VERSION "1.0.0"

NS_ :

BS_:

BU_: KRABBY_HOST LEG_NODE

BO_ 256 SET_DUTY: 36 KRABBY_HOST
 SG_ L1_J1 : 0|16@1- (0.001,0) [-1|1] "" KRABBY_HOST
 SG_ L1_J2 : 16|16@1- (0.001,0) [-1|1] "" KRABBY_HOST
 SG_ L1_J3 : 32|16@1- (0.001,0) [-1|1] "" KRABBY_HOST
 SG_ L2_J1 : 48|16@1- (0.001,0) [-1|1] "" KRABBY_HOST
 SG_ L2_J2 : 64|16@1- (0.001,0) [-1|1] "" KRABBY_HOST
 SG_ L2_J3 : 80|16@1- (0.001,0) [-1|1] "" KRABBY_HOST
 SG_ L3_J1 : 96|16@1- (0.001,0) [-1|1] "" KRABBY_HOST
 SG_ L3_J2 : 112|16@1- (0.001,0) [-1|1] "" KRABBY_HOST
 SG_ L3_J3 : 128|16@1- (0.001,0) [-1|1] "" KRABBY_HOST
 SG_ L4_J1 : 144|16@1- (0.001,0) [-1|1] "" KRABBY_HOST
 SG_ L4_J2 : 160|16@1- (0.001,0) [-1|1] "" KRABBY_HOST
 SG_ L4_J3 : 176|16@1- (0.001,0) [-1|1] "" KRABBY_HOST
 SG_ L5_J1 : 192|16@1- (0.001,0) [-1|1] "" KRABBY_HOST
 SG_ L5_J2 : 208|16@1- (0.001,0) [-1|1] "" KRABBY_HOST
 SG_ L5_J3 : 224|16@1- (0.001,0) [-1|1] "" KRABBY_HOST
 SG_ L6_J1 : 240|16@1- (0.001,0) [-1|1] "" KRABBY_HOST
 SG_ L6_J2 : 256|16@1- (0.001,0) [-1|1] "" KRABBY_HOST
 SG_ L6_J3 : 272|16@1- (0.001,0) [-1|1] "" KRABBY_HOST

BO_ 385 CALIBRATE_1: 1 KRABBY_HOST
 SG_ joint : 0|8@1+ (1,0) [2|3] "" KRABBY_HOST

BO_ 386 CALIBRATE_2: 1 KRABBY_HOST
 SG_ joint : 0|8@1+ (1,0) [2|3] "" KRABBY_HOST

BO_ 387 CALIBRATE_3: 1 KRABBY_HOST
 SG_ joint : 0|8@1+ (1,0) [2|3] "" KRABBY_HOST

BO_ 388 CALIBRATE_4: 1 KRABBY_HOST
 SG_ joint : 0|8@1+ (1,0) [2|3] "" KRABBY_HOST

BO_ 389 CALIBRATE_5: 1 KRABBY_HOST
 SG_ joint : 0|8@1+ (1,0) [2|3] "" KRABBY_HOST

BO_ 390 CALIBRATE_6: 1 KRABBY_HOST
 SG_ joint : 0|8@1+ (1,0) [2|3] "" KRABBY_HOST

BO_ 513 TELEMETRY_1: 48 LEG_NODE
 SG_ J1_HALL : 0|32@1- (1,0) [-2147483648|2147483647] "" KRABBY_HOST
 SG_ J1_DUTY : 32|16@1- (0.001,0) [-1|1] "" KRABBY_HOST
 SG_ J1_POT : 48|12@1+ (1,0) [0|4095] "" KRABBY_HOST
 SG_ J1_FAULT : 60|1@1+ (1,0) [0|1] "" KRABBY_HOST
 SG_ J1_CALIBRATING : 61|1@1+ (1,0) [0|1] "" KRABBY_HOST
 SG_ J1_CALIBRATED : 62|1@1+ (1,0) [0|1] "" KRABBY_HOST
 SG_ J1_POSITION : 64|64@1+ (1,0) [-1.7976931348623157E+308|1.7976931348623157E+308] "" KRABBY_HOST
 SG_ J2_HALL : 128|32@1- (1,0) [-2147483648|2147483647] "" KRABBY_HOST
 SG_ J2_DUTY : 160|16@1- (0.001,0) [-1|1] "" KRABBY_HOST
 SG_ J2_POT : 176|12@1+ (1,0) [0|4095] "" KRABBY_HOST
 SG_ J2_FAULT : 188|1@1+ (1,0) [0|1] "" KRABBY_HOST
 SG_ J2_CALIBRATING : 189|1@1+ (1,0) [0|1] "" KRABBY_HOST
 SG_ J2_CALIBRATED : 190|1@1+ (1,0) [0|1] "" KRABBY_HOST
 SG_ J2_POSITION : 192|64@1+ (1,0) [-1.7976931348623157E+308|1.7976931348623157E+308] "" KRABBY_HOST
 SG_ J3_HALL : 256|32@1- (1,0) [-2147483648|2147483647] "" KRABBY_HOST
 SG_ J3_DUTY : 288|16@1- (0.001,0) [-1|1] "" KRABBY_HOST
 SG_ J3_POT : 304|12@1+ (1,0) [0|4095] "" KRABBY_HOST
 SG_ J3_FAULT : 316|1@1+ (1,0) [0|1] "" KRABBY_HOST
 SG_ J3_CALIBRATING : 317|1@1+ (1,0) [0|1] "" KRABBY_HOST
 SG_ J3_CALIBRATED : 318|1@1+ (1,0) [0|1] "" KRABBY_HOST
 SG_ J3_POSITION : 320|64@1+ (1,0) [-1.7976931348623157E+308|1.7976931348623157E+308] "" KRABBY_HOST

BO_ 514 TELEMETRY_2: 48 LEG_NODE
 SG_ J1_HALL : 0|32@1- (1,0) [-2147483648|2147483647] "" KRABBY_HOST
 SG_ J1_DUTY : 32|16@1- (0.001,0) [-1|1] "" KRABBY_HOST
 SG_ J1_POT : 48|12@1+ (1,0) [0|4095] "" KRABBY_HOST
 SG_ J1_FAULT : 60|1@1+ (1,0) [0|1] "" KRABBY_HOST
 SG_ J1_CALIBRATING : 61|1@1+ (1,0) [0|1] "" KRABBY_HOST
 SG_ J1_CALIBRATED : 62|1@1+ (1,0) [0|1] "" KRABBY_HOST
 SG_ J1_POSITION : 64|64@1+ (1,0) [-1.7976931348623157E+308|1.7976931348623157E+308] "" KRABBY_HOST
 SG_ J2_HALL : 128|32@1- (1,0) [-2147483648|2147483647] "" KRABBY_HOST
 SG_ J2_DUTY : 160|16@1- (0.001,0) [-1|1] "" KRABBY_HOST
 SG_ J2_POT : 176|12@1+ (1,0) [0|4095] "" KRABBY_HOST
 SG_ J2_FAULT : 188|1@1+ (1,0) [0|1] "" KRABBY_HOST
 SG_ J2_CALIBRATING : 189|1@1+ (1,0) [0|1] "" KRABBY_HOST
 SG_ J2_CALIBRATED : 190|1@1+ (1,0) [0|1] "" KRABBY_HOST
 SG_ J2_POSITION : 192|64@1+ (1,0) [-1.7976931348623157E+308|1.7976931348623157E+308] "" KRABBY_HOST
 SG_ J3_HALL : 256|32@1- (1,0) [-2147483648|2147483647] "" KRABBY_HOST
 SG_ J3_DUTY : 288|16@1- (0.001,0) [-1|1] "" KRABBY_HOST
 SG_ J3_POT : 304|12@1+ (1,0) [0|4095] "" KRABBY_HOST
 SG_ J3_FAULT : 316|1@1+ (1,0) [0|1] "" KRABBY_HOST
 SG_ J3_CALIBRATING : 317|1@1+ (1,0) [0|1] "" KRABBY_HOST
 SG_ J3_CALIBRATED : 318|1@1+ (1,0) [0|1] "" KRABBY_HOST
 SG_ J3_POSITION : 320|64@1+ (1,0) [-1.7976931348623157E+308|1.7976931348623157E+308] "" KRABBY_HOST

BO_ 515 TELEMETRY_3: 48 LEG_NODE
 SG_ J1_HALL : 0|32@1- (1,0) [-2147483648|2147483647] "" KRABBY_HOST
 SG_ J1_DUTY : 32|16@1- (0.001,0) [-1|1] "" KRABBY_HOST
 SG_ J1_POT : 48|12@1+ (1,0) [0|4095] "" KRABBY_HOST
 SG_ J1_FAULT : 60|1@1+ (1,0) [0|1] "" KRABBY_HOST
 SG_ J1_CALIBRATING : 61|1@1+ (1,0) [0|1] "" KRABBY_HOST
 SG_ J1_CALIBRATED : 62|1@1+ (1,0) [0|1] "" KRABBY_HOST
 SG_ J1_POSITION : 64|64@1+ (1,0) [-1.7976931348623157E+308|1.7976931348623157E+308] "" KRABBY_HOST
 SG_ J2_HALL : 128|32@1- (1,0) [-2147483648|2147483647] "" KRABBY_HOST
 SG_ J2_DUTY : 160|16@1- (0.001,0) [-1|1] "" KRABBY_HOST
 SG_ J2_POT : 176|12@1+ (1,0) [0|4095] "" KRABBY_HOST
 SG_ J2_FAULT : 188|1@1+ (1,0) [0|1] "" KRABBY_HOST
 SG_ J2_CALIBRATING : 189|1@1+ (1,0) [0|1] "" KRABBY_HOST
 SG_ J2_CALIBRATED : 190|1@1+ (1,0) [0|1] "" KRABBY_HOST
 SG_ J2_POSITION : 192|64@1+ (1,0) [-1.7976931348623157E+308|1.7976931348623157E+308] "" KRABBY_HOST
 SG_ J3_HALL : 256|32@1- (1,0) [-2147483648|2147483647] "" KRABBY_HOST
 SG_ J3_DUTY : 288|16@1- (0.001,0) [-1|1] "" KRABBY_HOST
 SG_ J3_POT : 304|12@1+ (1,0) [0|4095] "" KRABBY_HOST
 SG_ J3_FAULT : 316|1@1+ (1,0) [0|1] "" KRABBY_HOST
 SG_ J3_CALIBRATING : 317|1@1+ (1,0) [0|1] "" KRABBY_HOST
 SG_ J3_CALIBRATED : 318|1@1+ (1,0) [0|1] "" KRABBY_HOST
 SG_ J3_POSITION : 320|64@1+ (1,0) [-1.7976931348623157E+308|1.7976931348623157E+308] "" KRABBY_HOST

BO_ 516 TELEMETRY_4: 48 LEG_NODE
 SG_ J1_HALL : 0|32@1- (1,0) [-2147483648|2147483647] "" KRABBY_HOST
 SG_ J1_DUTY : 32|16@1- (0.001,0) [-1|1] "" KRABBY_HOST
 SG_ J1_POT : 48|12@1+ (1,0) [0|4095] "" KRABBY_HOST
 SG_ J1_FAULT : 60|1@1+ (1,0) [0|1] "" KRABBY_HOST
 SG_ J1_CALIBRATING : 61|1@1+ (1,0) [0|1] "" KRABBY_HOST
 SG_ J1_CALIBRATED : 62|1@1+ (1,0) [0|1] "" KRABBY_HOST
 SG_ J1_POSITION : 64|64@1+ (1,0) [-1.7976931348623157E+308|1.7976931348623157E+308] "" KRABBY_HOST
 SG_ J2_HALL : 128|32@1- (1,0) [-2147483648|2147483647] "" KRABBY_HOST
 SG_ J2_DUTY : 160|16@1- (0.001,0) [-1|1] "" KRABBY_HOST
 SG_ J2_POT : 176|12@1+ (1,0) [0|4095] "" KRABBY_HOST
 SG_ J2_FAULT : 188|1@1+ (1,0) [0|1] "" KRABBY_HOST
 SG_ J2_CALIBRATING : 189|1@1+ (1,0) [0|1] "" KRABBY_HOST
 SG_ J2_CALIBRATED : 190|1@1+ (1,0) [0|1] "" KRABBY_HOST
 SG_ J2_POSITION : 192|64@1+ (1,0) [-1.7976931348623157E+308|1.7976931348623157E+308] "" KRABBY_HOST
 SG_ J3_HALL : 256|32@1- (1,0) [-2147483648|2147483647] "" KRABBY_HOST
 SG_ J3_DUTY : 288|16@1- (0.001,0) [-1|1] "" KRABBY_HOST
 SG_ J3_POT : 304|12@1+ (1,0) [0|4095] "" KRABBY_HOST
 SG_ J3_FAULT : 316|1@1+ (1,0) [0|1] "" KRABBY_HOST
 SG_ J3_CALIBRATING : 317|1@1+ (1,0) [0|1] "" KRABBY_HOST
 SG_ J3_CALIBRATED : 318|1@1+ (1,0) [0|1] "" KRABBY_HOST
 SG_ J3_POSITION : 320|64@1+ (1,0) [-1.7976931348623157E+308|1.7976931348623157E+308] "" KRABBY_HOST

BO_ 517 TELEMETRY_5: 48 LEG_NODE
 SG_ J1_HALL : 0|32@1- (1,0) [-2147483648|2147483647] "" KRABBY_HOST
 SG_ J1_DUTY : 32|16@1- (0.001,0) [-1|1] "" KRABBY_HOST
 SG_ J1_POT : 48|12@1+ (1,0) [0|4095] "" KRABBY_HOST
 SG_ J1_FAULT : 60|1@1+ (1,0) [0|1] "" KRABBY_HOST
 SG_ J1_CALIBRATING : 61|1@1+ (1,0) [0|1] "" KRABBY_HOST
 SG_ J1_CALIBRATED : 62|1@1+ (1,0) [0|1] "" KRABBY_HOST
 SG_ J1_POSITION : 64|64@1+ (1,0) [-1.7976931348623157E+308|1.7976931348623157E+308] "" KRABBY_HOST
 SG_ J2_HALL : 128|32@1- (1,0) [-2147483648|2147483647] "" KRABBY_HOST
 SG_ J2_DUTY : 160|16@1- (0.001,0) [-1|1] "" KRABBY_HOST
 SG_ J2_POT : 176|12@1+ (1,0) [0|4095] "" KRABBY_HOST
 SG_ J2_FAULT : 188|1@1+ (1,0) [0|1] "" KRABBY_HOST
 SG_ J2_CALIBRATING : 189|1@1+ (1,0) [0|1] "" KRABBY_HOST
 SG_ J2_CALIBRATED : 190|1@1+ (1,0) [0|1] "" KRABBY_HOST
 SG_ J2_POSITION : 192|64@1+ (1,0) [-1.7976931348623157E+308|1.7976931348623157E+308] "" KRABBY_HOST
 SG_ J3_HALL : 256|32@1- (1,0) [-2147483648|2147483647] "" KRABBY_HOST
 SG_ J3_DUTY : 288|16@1- (0.001,0) [-1|1] "" KRABBY_HOST
 SG_ J3_POT : 304|12@1+ (1,0) [0|4095] "" KRABBY_HOST
 SG_ J3_FAULT : 316|1@1+ (1,0) [0|1] "" KRABBY_HOST
 SG_ J3_CALIBRATING : 317|1@1+ (1,0) [0|1] "" KRABBY_HOST
 SG_ J3_CALIBRATED : 318|1@1+ (1,0) [0|1] "" KRABBY_HOST
 SG_ J3_POSITION : 320|64@1+ (1,0) [-1.7976931348623157E+308|1.7976931348623157E+308] "" KRABBY_HOST

BO_ 518 TELEMETRY_6: 48 LEG_NODE
 SG_ J1_HALL : 0|32@1- (1,0) [-2147483648|2147483647] "" KRABBY_HOST
 SG_ J1_DUTY : 32|16@1- (0.001,0) [-1|1] "" KRABBY_HOST
 SG_ J1_POT : 48|12@1+ (1,0) [0|4095] "" KRABBY_HOST
 SG_ J1_FAULT : 60|1@1+ (1,0) [0|1] "" KRABBY_HOST
 SG_ J1_CALIBRATING : 61|1@1+ (1,0) [0|1] "" KRABBY_HOST
 SG_ J1_CALIBRATED : 62|1@1+ (1,0) [0|1] "" KRABBY_HOST
 SG_ J1_POSITION : 64|64@1+ (1,0) [-1.7976931348623157E+308|1.7976931348623157E+308] "" KRABBY_HOST
 SG_ J2_HALL : 128|32@1- (1,0) [-2147483648|2147483647] "" KRABBY_HOST
 SG_ J2_DUTY : 160|16@1- (0.001,0) [-1|1] "" KRABBY_HOST
 SG_ J2_POT : 176|12@1+ (1,0) [0|4095] "" KRABBY_HOST
 SG_ J2_FAULT : 188|1@1+ (1,0) [0|1] "" KRABBY_HOST
 SG_ J2_CALIBRATING : 189|1@1+ (1,0) [0|1] "" KRABBY_HOST
 SG_ J2_CALIBRATED : 190|1@1+ (1,0) [0|1] "" KRABBY_HOST
 SG_ J2_POSITION : 192|64@1+ (1,0) [-1.7976931348623157E+308|1.7976931348623157E+308] "" KRABBY_HOST
 SG_ J3_HALL : 256|32@1- (1,0) [-2147483648|2147483647] "" KRABBY_HOST
 SG_ J3_DUTY : 288|16@1- (0.001,0) [-1|1] "" KRABBY_HOST
 SG_ J3_POT : 304|12@1+ (1,0) [0|4095] "" KRABBY_HOST
 SG_ J3_FAULT : 316|1@1+ (1,0) [0|1] "" KRABBY_HOST
 SG_ J3_CALIBRATING : 317|1@1+ (1,0) [0|1] "" KRABBY_HOST
 SG_ J3_CALIBRATED : 318|1@1+ (1,0) [0|1] "" KRABBY_HOST
 SG_ J3_POSITION : 320|64@1+ (1,0) [-1.7976931348623157E+308|1.7976931348623157E+308] "" KRABBY_HOST

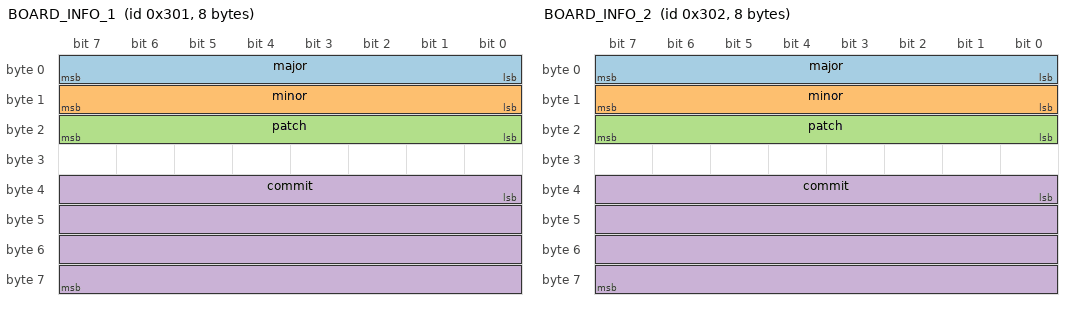
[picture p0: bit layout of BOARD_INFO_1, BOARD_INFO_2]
BO_ 769 BOARD_INFO_1: 8 LEG_NODE
 SG_ major : 0|8@1+ (1,0) [0|255] "" KRABBY_HOST
 SG_ minor : 8|8@1+ (1,0) [0|255] "" KRABBY_HOST
 SG_ patch : 16|8@1+ (1,0) [0|255] "" KRABBY_HOST
 SG_ commit : 32|32@1+ (1,0) [0|4294967295] "" KRABBY_HOST

BO_ 770 BOARD_INFO_2: 8 LEG_NODE
 SG_ major : 0|8@1+ (1,0) [0|255] "" KRABBY_HOST
 SG_ minor : 8|8@1+ (1,0) [0|255] "" KRABBY_HOST
 SG_ patch : 16|8@1+ (1,0) [0|255] "" KRABBY_HOST
 SG_ commit : 32|32@1+ (1,0) [0|4294967295] "" KRABBY_HOST

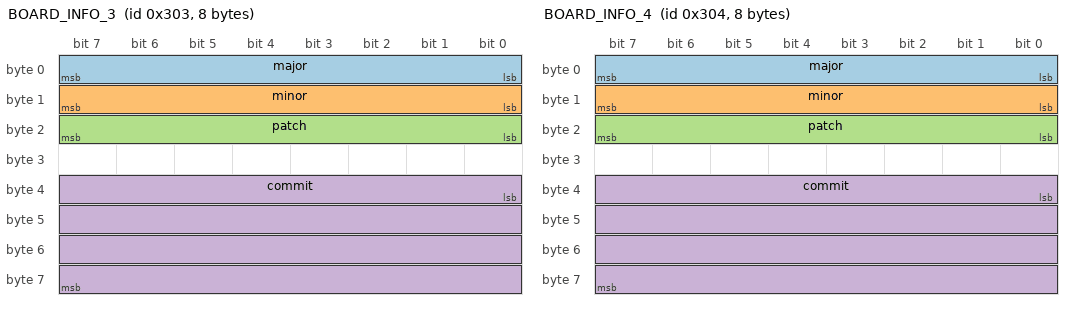
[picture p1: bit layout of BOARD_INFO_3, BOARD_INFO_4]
BO_ 771 BOARD_INFO_3: 8 LEG_NODE
 SG_ major : 0|8@1+ (1,0) [0|255] "" KRABBY_HOST
 SG_ minor : 8|8@1+ (1,0) [0|255] "" KRABBY_HOST
 SG_ patch : 16|8@1+ (1,0) [0|255] "" KRABBY_HOST
 SG_ commit : 32|32@1+ (1,0) [0|4294967295] "" KRABBY_HOST

BO_ 772 BOARD_INFO_4: 8 LEG_NODE
 SG_ major : 0|8@1+ (1,0) [0|255] "" KRABBY_HOST
 SG_ minor : 8|8@1+ (1,0) [0|255] "" KRABBY_HOST
 SG_ patch : 16|8@1+ (1,0) [0|255] "" KRABBY_HOST
 SG_ commit : 32|32@1+ (1,0) [0|4294967295] "" KRABBY_HOST

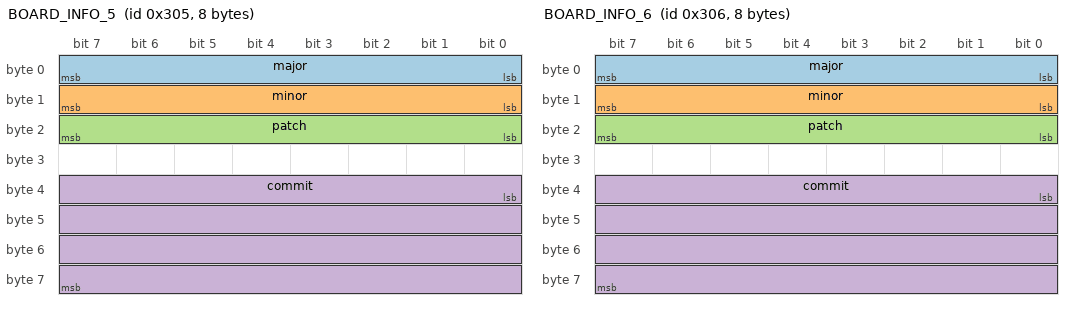
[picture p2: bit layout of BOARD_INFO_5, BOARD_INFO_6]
BO_ 773 BOARD_INFO_5: 8 LEG_NODE
 SG_ major : 0|8@1+ (1,0) [0|255] "" KRABBY_HOST
 SG_ minor : 8|8@1+ (1,0) [0|255] "" KRABBY_HOST
 SG_ patch : 16|8@1+ (1,0) [0|255] "" KRABBY_HOST
 SG_ commit : 32|32@1+ (1,0) [0|4294967295] "" KRABBY_HOST

BO_ 774 BOARD_INFO_6: 8 LEG_NODE
 SG_ major : 0|8@1+ (1,0) [0|255] "" KRABBY_HOST
 SG_ minor : 8|8@1+ (1,0) [0|255] "" KRABBY_HOST
 SG_ patch : 16|8@1+ (1,0) [0|255] "" KRABBY_HOST
 SG_ commit : 32|32@1+ (1,0) [0|4294967295] "" KRABBY_HOST

BA_DEF_ BO_  "VFrameFormat" ENUM  "StandardCAN","ExtendedCAN","reserved","J1939PG","reserved","reserved","reserved","reserved","reserved","reserved","reserved","reserved","reserved","reserved","StandardCAN_FD","ExtendedCAN_FD";
BA_DEF_DEF_  "VFrameFormat" "0";
BA_ "VFrameFormat" BO_ 256 14;
BA_ "VFrameFormat" BO_ 385 14;
BA_ "VFrameFormat" BO_ 386 14;
BA_ "VFrameFormat" BO_ 387 14;
BA_ "VFrameFormat" BO_ 388 14;
BA_ "VFrameFormat" BO_ 389 14;
BA_ "VFrameFormat" BO_ 390 14;
BA_ "VFrameFormat" BO_ 513 14;
BA_ "VFrameFormat" BO_ 514 14;
BA_ "VFrameFormat" BO_ 515 14;
BA_ "VFrameFormat" BO_ 516 14;
BA_ "VFrameFormat" BO_ 517 14;
BA_ "VFrameFormat" BO_ 518 14;
BA_ "VFrameFormat" BO_ 769 14;
BA_ "VFrameFormat" BO_ 770 14;
BA_ "VFrameFormat" BO_ 771 14;
BA_ "VFrameFormat" BO_ 772 14;
BA_ "VFrameFormat" BO_ 773 14;
BA_ "VFrameFormat" BO_ 774 14;
